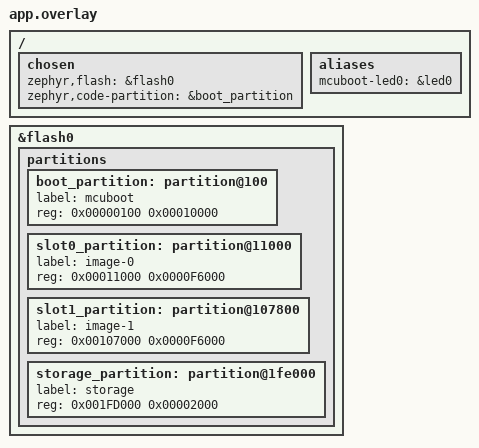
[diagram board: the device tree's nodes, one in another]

/ {
    chosen {
        // zephyr,console = &uart0;
        // zephyr,shell-uart = &uart0;
        zephyr,flash = &flash0;
        zephyr,code-partition = &boot_partition;
    };
    
    aliases{
        mcuboot-led0 = &led0;
    };
};
    
&flash0{
    partitions {
        boot_partition: partition@100 {
            label = "mcuboot";
            reg = <0x00000100 0x00010000>;
        };
        slot0_partition: partition@11000 { //Slots has to be align of 0x1000
            label = "image-0";
            reg = <0x00011000 0x0000F6000>;
        };
        slot1_partition: partition@107800 {
            label = "image-1";
            reg = <0x00107000 0x0000F6000>;
        };
        storage_partition: partition@1fe000 {
            label = "storage";
            reg = <0x001FD000 0x00002000>;
        };

    };
};

